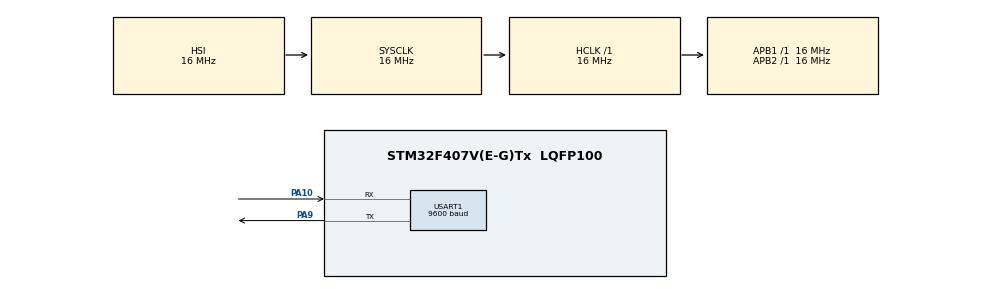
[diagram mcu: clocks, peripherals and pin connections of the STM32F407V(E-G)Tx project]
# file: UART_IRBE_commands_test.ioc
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Mcu.Family=STM32F4
Mcu.Name=STM32F407V(E-G)Tx
Mcu.Package=LQFP100
NVIC.PriorityGroup=NVIC_PRIORITYGROUP_4
NVIC.TIM3_IRQn=true\:0\:0\:false\:false\:true\:true\:true\:true
NVIC.USART1_IRQn=true\:0\:0\:false\:false\:true\:true\:true\:true
PA10.Mode=Asynchronous
PA10.Signal=USART1_RX
PA13.Mode=Serial_Wire
PA13.Signal=SYS_JTMS-SWDIO
PA14.Mode=Serial_Wire
PA14.Signal=SYS_JTCK-SWCLK
PA9.Mode=Asynchronous
PA9.Signal=USART1_TX
ProjectManager.HeapSize=0x200
ProjectManager.StackSize=0x400
ProjectManager.TargetToolchain=STM32CubeIDE
RCC.AHBFreq_Value=16000000
RCC.APB1Freq_Value=16000000
RCC.APB2Freq_Value=16000000
RCC.CortexFreq_Value=16000000
RCC.HSE_VALUE=25000000
RCC.HSI_VALUE=16000000
RCC.LSE_VALUE=32768
RCC.SYSCLKFreq_VALUE=16000000
RCC.VCOOutputFreq_Value=192000000
TIM3.Period=1000
TIM3.Prescaler=16000
USART1.BaudRate=9600
USART1.VirtualMode=VM_ASYNC
VP_RTC_VS_RTC_Activate.Mode=RTC_Enabled
VP_TIM3_VS_ClockSourceINT.Mode=Internal
board=custom

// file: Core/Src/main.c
/* USER CODE BEGIN Header */
/**
  ******************************************************************************
  * @file           : main.c
  * @brief          : Main program body
  ******************************************************************************
  * @attention
  *
  * Copyright (c) 2024 STMicroelectronics.
  * All rights reserved.
  *
  * This software is licensed under terms that can be found in the LICENSE file
  * in the root directory of this software component.
  * If no LICENSE file comes with this software, it is provided AS-IS.
  *
  ******************************************************************************
  */
/* USER CODE END Header */
#include "main.h"

/* USER CODE BEGIN Includes */
#include <stdio.h>
#include <string.h>
/* USER CODE END Includes */

RTC_HandleTypeDef hrtc;

TIM_HandleTypeDef htim3;

UART_HandleTypeDef huart1;

void SystemClock_Config(void);
static void MX_GPIO_Init(void);
static void MX_RTC_Init(void);
static void MX_TIM3_Init(void);
static void MX_USART1_UART_Init(void);
/* USER CODE BEGIN PFP */

void processReceivedMessage(uint8_t *buffer);
void sendResponse(const char *response);

/* USER CODE END PFP */

/* USER CODE BEGIN 0 */

char receivedMessage[10]; // Variable to store received message
uint8_t USARTRxBuffer [10] = {0};
uint8_t USARTTxBuffer[4];

RTC_DateTypeDef	systemRTCDate;
RTC_TimeTypeDef	systemRTCTime;

uint8_t tim3Flag = 0;
uint16_t myCnt[10] = {0};

void processReceivedMessage(uint8_t *buffer) {
//    // Compare the received message with "<ENI>"
//    if (strcmp((char *)buffer, "<ENI>") == 0) {
//        // If the received message is "<ENI>", send "<OK>" through USART1
//    	sendResponse("<OK>");
//    } else {
//        // If the received message is something else, send "<NOK>" through USART1
//    	sendResponse("<NOK>");
//    }

	// Compare the received message with "<ENI>"
	    if (strncmp((char *)buffer, "<ENI>", 5) == 0) { // Compare first 5 characters
	        // If the received message is "<ENI>", send "<OK>" through USART1
	        sendResponse("<OK>");
	    } else {
	        // If the received message is something else, send "<NOK>" through USART1
	        sendResponse("<NOK>");
	    }

}

void sendResponse(const char *response) {
//    // Send the response through USART1
//    HAL_UART_Transmit(&huart1, (uint8_t *)response, strlen(response), 100);

	// Send the response through USART1
	    HAL_UART_Transmit(&huart1, (uint8_t *)response, strlen(response), HAL_MAX_DELAY);

}

/* USER CODE END 0 */

int main(void)
{

  /* MCU Configuration--------------------------------------------------------*/

  /* Reset of all peripherals, Initializes the Flash interface and the Systick. */
  HAL_Init();

  /* Configure the system clock */
  SystemClock_Config();

  /* Initialize all configured peripherals */
  MX_GPIO_Init();
  MX_RTC_Init();
  MX_TIM3_Init();
  MX_USART1_UART_Init();
  /* USER CODE BEGIN 2 */

  HAL_TIM_Base_Start_IT(&htim3);

  HAL_UART_Receive_IT(&huart1, USARTRxBuffer, 5);

  /* USER CODE END 2 */

  /* Infinite loop */
  while (1)
  {

    /* USER CODE BEGIN 3 */
	  if(tim3Flag == 1){
		  HAL_RTC_GetTime(&hrtc, &systemRTCTime, RTC_FORMAT_BIN);
		  HAL_RTC_GetDate(&hrtc, &systemRTCDate, RTC_FORMAT_BIN);
		  tim3Flag = 0;
	  }

  }
  /* USER CODE END 3 */
}

void SystemClock_Config(void)
{
  RCC_OscInitTypeDef RCC_OscInitStruct = {0};
  RCC_ClkInitTypeDef RCC_ClkInitStruct = {0};

  /** Configure the main internal regulator output voltage
  */
  __HAL_RCC_PWR_CLK_ENABLE();
  __HAL_PWR_VOLTAGESCALING_CONFIG(PWR_REGULATOR_VOLTAGE_SCALE1);

  /** Initializes the RCC Oscillators according to the specified parameters
  * in the RCC_OscInitTypeDef structure.
  */
  RCC_OscInitStruct.OscillatorType = RCC_OSCILLATORTYPE_HSI|RCC_OSCILLATORTYPE_LSI;
  RCC_OscInitStruct.HSIState = RCC_HSI_ON;
  RCC_OscInitStruct.HSICalibrationValue = RCC_HSICALIBRATION_DEFAULT;
  RCC_OscInitStruct.LSIState = RCC_LSI_ON;
  RCC_OscInitStruct.PLL.PLLState = RCC_PLL_NONE;
  if (HAL_RCC_OscConfig(&RCC_OscInitStruct) != HAL_OK)
  {
    Error_Handler();
  }

  /** Initializes the CPU, AHB and APB buses clocks
  */
  RCC_ClkInitStruct.ClockType = RCC_CLOCKTYPE_HCLK|RCC_CLOCKTYPE_SYSCLK
                              |RCC_CLOCKTYPE_PCLK1|RCC_CLOCKTYPE_PCLK2;
  RCC_ClkInitStruct.SYSCLKSource = RCC_SYSCLKSOURCE_HSI;
  RCC_ClkInitStruct.AHBCLKDivider = RCC_SYSCLK_DIV1;
  RCC_ClkInitStruct.APB1CLKDivider = RCC_HCLK_DIV1;
  RCC_ClkInitStruct.APB2CLKDivider = RCC_HCLK_DIV1;

  if (HAL_RCC_ClockConfig(&RCC_ClkInitStruct, FLASH_LATENCY_0) != HAL_OK)
  {
    Error_Handler();
  }
}

static void MX_RTC_Init(void)
{

  /** Initialize RTC Only
  */
  hrtc.Instance = RTC;
  hrtc.Init.HourFormat = RTC_HOURFORMAT_24;
  hrtc.Init.AsynchPrediv = 127;
  hrtc.Init.SynchPrediv = 255;
  hrtc.Init.OutPut = RTC_OUTPUT_DISABLE;
  hrtc.Init.OutPutPolarity = RTC_OUTPUT_POLARITY_HIGH;
  hrtc.Init.OutPutType = RTC_OUTPUT_TYPE_OPENDRAIN;
  if (HAL_RTC_Init(&hrtc) != HAL_OK)
  {
    Error_Handler();
  }

}

static void MX_TIM3_Init(void)
{

  TIM_ClockConfigTypeDef sClockSourceConfig = {0};
  TIM_MasterConfigTypeDef sMasterConfig = {0};

  htim3.Instance = TIM3;
  htim3.Init.Prescaler = 16000;
  htim3.Init.CounterMode = TIM_COUNTERMODE_UP;
  htim3.Init.Period = 1000;
  htim3.Init.ClockDivision = TIM_CLOCKDIVISION_DIV1;
  htim3.Init.AutoReloadPreload = TIM_AUTORELOAD_PRELOAD_DISABLE;
  if (HAL_TIM_Base_Init(&htim3) != HAL_OK)
  {
    Error_Handler();
  }
  sClockSourceConfig.ClockSource = TIM_CLOCKSOURCE_INTERNAL;
  if (HAL_TIM_ConfigClockSource(&htim3, &sClockSourceConfig) != HAL_OK)
  {
    Error_Handler();
  }
  sMasterConfig.MasterOutputTrigger = TIM_TRGO_RESET;
  sMasterConfig.MasterSlaveMode = TIM_MASTERSLAVEMODE_DISABLE;
  if (HAL_TIMEx_MasterConfigSynchronization(&htim3, &sMasterConfig) != HAL_OK)
  {
    Error_Handler();
  }

}

static void MX_USART1_UART_Init(void)
{

  huart1.Instance = USART1;
  huart1.Init.BaudRate = 9600;
  huart1.Init.WordLength = UART_WORDLENGTH_8B;
  huart1.Init.StopBits = UART_STOPBITS_1;
  huart1.Init.Parity = UART_PARITY_NONE;
  huart1.Init.Mode = UART_MODE_TX_RX;
  huart1.Init.HwFlowCtl = UART_HWCONTROL_NONE;
  huart1.Init.OverSampling = UART_OVERSAMPLING_16;
  if (HAL_UART_Init(&huart1) != HAL_OK)
  {
    Error_Handler();
  }

}

static void MX_GPIO_Init(void)
{

  /* GPIO Ports Clock Enable */
  __HAL_RCC_GPIOA_CLK_ENABLE();

}

/* USER CODE BEGIN 4 */

void HAL_TIM_PeriodElapsedCallback(TIM_HandleTypeDef *htim)
{
	if (htim == &htim3)
	{
		tim3Flag = 1;
		myCnt[0]++;
	}
}

void HAL_UART_RxCpltCallback(UART_HandleTypeDef *huart)
{
//	if (huart->Instance == USART1) {
//	    // Restart reception for the next message
//	    HAL_UART_Receive_IT(&huart1, USARTRxBuffer, 5);
//
//	    // Process the received message
//	    processReceivedMessage(USARTRxBuffer);
//
//	    // Clear the receive buffer
//	    memset(USARTRxBuffer, 0, sizeof(USARTRxBuffer));
//	}

	if (huart->Instance == USART1) {
	        // Process the received message
	        processReceivedMessage(USARTRxBuffer);

	        // Clear the receive buffer after processing and transmission
	        memset(USARTRxBuffer, 0, sizeof(USARTRxBuffer));

	        // Restart reception for the next message
	        HAL_UART_Receive_IT(&huart1, USARTRxBuffer, 10);
	    }

}

/* USER CODE END 4 */

void Error_Handler(void)
{
  __disable_irq();
  while (1)
  {
  }
}
